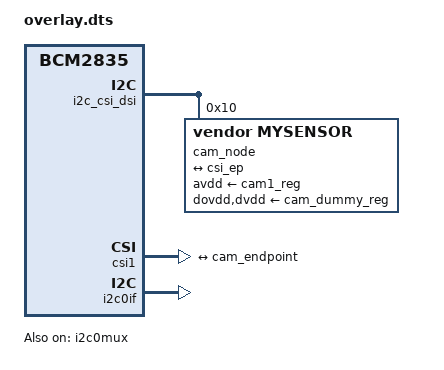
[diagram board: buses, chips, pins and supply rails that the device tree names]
// SPDX-License-Identifier: GPL-2.0-only
/*
 * Device Tree overlay TEMPLATE: MIPI CSI-2 camera sensor on the Raspberry Pi
 * camera connector (Raspberry Pi kernel tree, rpi-6.6.y).
 *
 * Labels used below (csi1, i2c_csi_dsi, i2c0if, i2c0mux, cam1_reg, cam1_clk,
 * cam_dummy_reg) are defined by the Raspberry Pi base DTs
 * (arch/arm/boot/dts/broadcom/bcm270x.dtsi and the per-board dts). They are
 * NOT upstream labels. Confirm each one exists in the base DT you boot:
 *
 *   dtc -I fs -O dts /proc/device-tree | grep -n 'cam1_\|csi\|i2c0mux'
 *   (or build the base dtb with DTC_FLAGS=-@ and read __symbols__)
 *
 * Everything tagged TODO(board) / TODO(datasheet) must come from the camera
 * module schematic and the sensor datasheet, not from memory. In particular:
 * I2C address, number of wired CSI-2 lanes, XCLK frequency, link frequency,
 * and which supplies the module actually uses.
 */
/dts-v1/;
/plugin/;

/ {
	compatible = "brcm,bcm2835";

	/* Sensor node on the VideoCore-owned camera/display I2C bus. */
	i2c_frag: fragment@0 {
		target = <&i2c_csi_dsi>;
		__overlay__ {
			#address-cells = <1>;
			#size-cells = <0>;
			status = "okay";

			cam_node: mysensor@10 {		/* TODO(board): I2C address */
				compatible = "vendor,mysensor";	/* TODO: real compatible */
				reg = <0x10>;		/* TODO(board): I2C address */
				status = "okay";

				clocks = <&cam1_clk>;
				avdd-supply = <&cam1_reg>;	/* TODO(board) */
				dovdd-supply = <&cam_dummy_reg>;/* TODO(board) */
				dvdd-supply = <&cam_dummy_reg>;	/* TODO(board) */

				rotation = <0>;
				orientation = <2>;	/* 2 = external */

				port {
					cam_endpoint: endpoint {
						data-lanes = <1 2>;	/* TODO(board): wired lanes */
						clock-noncontinuous;	/* TODO(datasheet) */
						link-frequencies =
							/bits/ 64 <400000000>;	/* TODO(datasheet) */
						remote-endpoint = <&csi_ep>;
					};
				};
			};
		};
	};

	/* Unicam receiver: enable it and point it at the sensor. */
	csi_frag: fragment@1 {
		target = <&csi1>;
		__overlay__ {
			status = "okay";
			brcm,media-controller;

			port {
				csi_ep: endpoint {
					remote-endpoint = <&cam_endpoint>;
					data-lanes = <1 2>;	/* TODO(board): wired lanes */
					clock-noncontinuous;	/* TODO(datasheet) */
				};
			};
		};
	};

	/* The mux that routes I2C0 to the camera connector. */
	fragment@2 {
		target = <&i2c0if>;
		__overlay__ {
			status = "okay";
		};
	};

	fragment@3 {
		target = <&i2c0mux>;
		__overlay__ {
			status = "okay";
		};
	};

	/* Power-up delay of the camera supply. TODO(datasheet). */
	reg_frag: fragment@4 {
		target = <&cam1_reg>;
		__overlay__ {
			startup-delay-us = <20000>;
		};
	};

	/* XCLK. Must equal MYSENSOR_XCLK_HZ in the driver. TODO(datasheet). */
	clk_frag: fragment@5 {
		target = <&cam1_clk>;
		__overlay__ {
			status = "okay";
			clock-frequency = <24000000>;
		};
	};

	__overrides__ {
		rotation = <&cam_node>, "rotation:0";
		orientation = <&cam_node>, "orientation:0";
	};
};
